# nrf9220_celldsp register map
Vendor: Nordic Semiconductor; Series: nRF92; File version: 1
Registers are 32-bit, read-write, reset 0x0 unless marked. A register's access mark holds for its fields unless they carry their own. Offsets are from the block's base; [hi:lo] are bit positions; lines under a group give offsets from that group; {n}, {i} and the like mark numbered series; 'fields as' and 'values as' point back to an identical list.

## GLOBAL_AHBBUFFER_APP — AHB Buffer 0
Base 0x5F90A000
Same registers: GLOBAL_AHBBUFFER_CELL 0x5F90C000
0x100 EVENTS_BUSERROR — Error response to posted write
  [0] EVENTS_BUSERROR
    0=NotGenerated (Event not generated); 1=Generated (Event generated)
0x200 SHORTS — Shortcuts between local events and tasks
0x300 INTEN — Enable or disable interrupt
  [0] BUSERROR — Enable or disable interrupt for event BUSERROR
    0=Disabled; 1=Enabled
0x304 INTENSET — Enable interrupt
  [0] BUSERROR — Write '1' to enable interrupt for event BUSERROR
    on read: 0=Disabled (Read: Disabled); 1=Enabled (Read: Enabled) | on write: 1=Set (Enable)
0x308 INTENCLR — Disable interrupt
  [0] BUSERROR — Write '1' to disable interrupt for event BUSERROR
    on read: 0=Disabled (Read: Disabled); 1=Enabled (Read: Enabled) | on write: 1=Clear (Disable)
0x30C INTPEND ro — Pending interrupts
  [0] BUSERROR — Read pending status of interrupt for event BUSERROR
    on read: 0=NotPending (Read: Not pending); 1=Pending (Read: Pending)
0x500 OPMODE — Operation mode
  [1:0] OPMODE
    0=f0 (Bypass); 1=f1 (Post all writes); 2=f2 (Obey hposted input); 3=f3 (Take OpMode from port)
0x504 ERRORADDRENABLE — Enable bit for error address tracking
  [0] ERRORADDRENABLE — Tracking must be enabled when it is needed. Detected error response for posted write (EVENT BUSERROR) will halt tracking and change the value of this register to 0.
    0=e0 (Error address is not tracked); 1=e1 (Error address is tracked)
0x508 ERRORADDR — Address for posted write error response
  [31:0] ERRORADDR — First address that caused error response for posted write. Valid only when EVENT BUSERROR is 1.

## GLOBAL_EGU130 — Event generator unit
Base 0x5F92D000
{0x0+4i} TASKS_TRIGGER[{i}] (i=0..15) wo — Description collection: Trigger n for triggering the corresponding TRIGGERED[n] event
  [0] TASKS_TRIGGER — Trigger n for triggering the corresponding TRIGGERED[n] event
    1=Trigger task
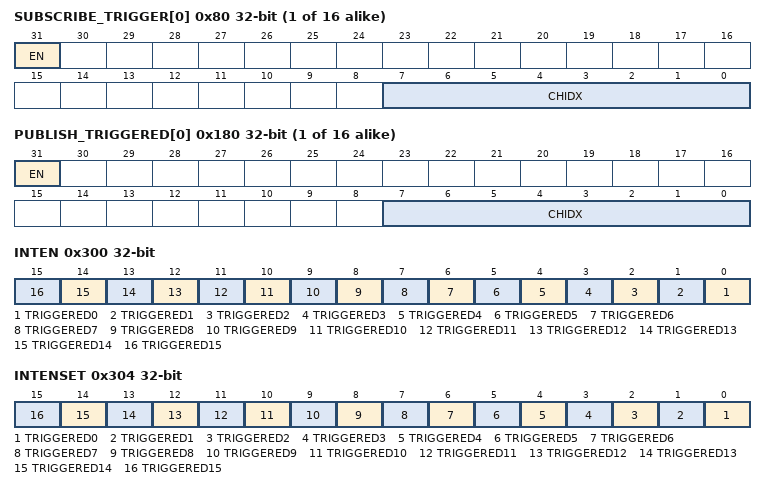
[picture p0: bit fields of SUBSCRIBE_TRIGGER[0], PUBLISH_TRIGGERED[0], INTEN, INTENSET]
{0x80+4i} SUBSCRIBE_TRIGGER[{i}] (i=0..15) — Description collection: Subscribe configuration for task TRIGGER[n]
  [31] EN
    0=Disabled (Disable subscription); 1=Enabled (Enable subscription)
  [7:0] CHIDX — DPPI channel that task TRIGGER[n] will subscribe to
{0x100+4i} EVENTS_TRIGGERED[{i}] (i=0..15) — Description collection: Event number n generated by triggering the corresponding TRIGGER[n] task
  [0] EVENTS_TRIGGERED — Event number n generated by triggering the corresponding TRIGGER[n] task
    0=NotGenerated (Event not generated); 1=Generated (Event generated)
{0x180+4i} PUBLISH_TRIGGERED[{i}] (i=0..15) — Description collection: Publish configuration for event TRIGGERED[n]
  [31] EN
    0=Disabled (Disable publishing); 1=Enabled (Enable publishing)
  [7:0] CHIDX — DPPI channel that event TRIGGERED[n] will publish to
0x300 INTEN — Enable or disable interrupt
  [all] fields
    0=Disabled; 1=Enabled
  [n] TRIGGERED{n} (n=0..15) — Enable or disable interrupt for event TRIGGERED[{n}]
0x304 INTENSET — Enable interrupt
  [all] fields
    on read: 0=Disabled (Read: Disabled); 1=Enabled (Read: Enabled) | on write: 1=Set (Enable)
  [n] TRIGGERED{n} (n=0..15) — Write '1' to enable interrupt for event TRIGGERED[{n}]
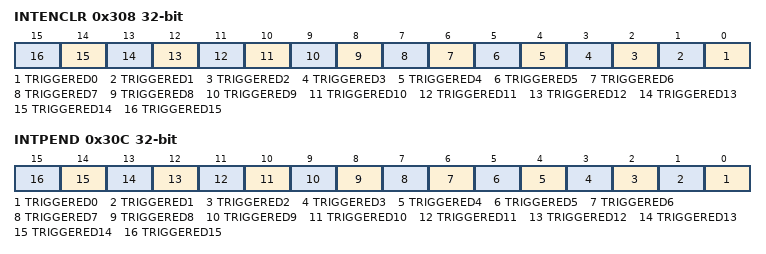
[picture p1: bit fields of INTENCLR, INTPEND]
0x308 INTENCLR — Disable interrupt
  [all] fields
    on read: 0=Disabled (Read: Disabled); 1=Enabled (Read: Enabled) | on write: 1=Clear (Disable)
  [n] TRIGGERED{n} (n=0..15) — Write '1' to disable interrupt for event TRIGGERED[{n}]
0x30C INTPEND ro — Pending interrupts
  [all] fields
    on read: 0=NotPending (Read: Not pending); 1=Pending (Read: Pending)
  [n] TRIGGERED{n} (n=0..15) — Read pending status of interrupt for event TRIGGERED[{n}]

## GLOBAL_GPIOINTERNAL — GPIO Internal
Base 0x5F939E00
0x40 LATCHCLRWAITCNT reset 0x2 — Select the number of wait cycles inserted on the bus when a LATCH register is cleared.
  [1:0] LATCHCLRWAITCNT
0x44 FORCELDETECTLOWCNT reset 0x8 — Select the number of cycles that LDETECT is forced low after clearing a LATCH register.
  [3:0] FORCELDETECTLOWCNT
0x48 RESET — Reset all GPIO registers.
  [0] RESET
    1=RESET (Trigger reset); 0=NA (No effect)
0x4C SENSECONFIGCHANGECNT reset 0x3 — Selects the number of cycles before the SENSE configuration takes effect when it is changed. Setting this register lower than the reset value can lead to unwanted LATCH set when SENSE and INPUT fields (PIN[n].CNF) are changed simultaneously.
  [2:0] SENSECONFIGCHANGECNT — Selects the number of cycles before the SENSE configuration takes effect when it is changed.
0x160 PCGC group — Unspecified
  0x00 TURNOFFAUTOCLOCKSOURCEREQ ro — No functionality
  {0x20+4j} PENALTY[{j}] (j=0..4) ro — Description collection: Penalty level for power/clock pair n
    [7:0] PENALTY — Penalty level
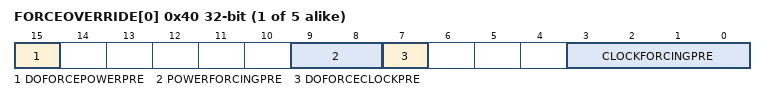
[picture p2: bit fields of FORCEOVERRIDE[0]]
  {0x40+4j} FORCEOVERRIDE[{j}] (j=0..4) ro — Description collection: Force override of power/clock pair n
    [15] DOFORCEPOWERPRE, [9:8] POWERFORCINGPRE, [7] DOFORCECLOCKPRE, [3:0] CLOCKFORCINGPRE

## GLOBAL_AUDIOPLLPM — AUXPM
Base 0x5F968000
0x20 TASKS_START wo — Request power up
  [0] TASKS_START
    1=Trigger task
0x24 TASKS_STOP wo — Stop requesting power up
  [0] TASKS_STOP
    1=Trigger task
0x110 EVENTS_SETTLED — LDO settled
  [0] EVENTS_SETTLED
    0=NotGenerated (Event not generated); 1=Generated (Event generated)
0x300 INTEN — Enable or disable interrupt
  [4] SETTLED — Enable or disable interrupt for event SETTLED
    0=Disabled; 1=Enabled
0x304 INTENSET — Enable interrupt
  [4] SETTLED — Write '1' to enable interrupt for event SETTLED
    on read: 0=Disabled (Read: Disabled); 1=Enabled (Read: Enabled) | on write: 1=Set (Enable)
0x308 INTENCLR — Disable interrupt
  [4] SETTLED — Write '1' to disable interrupt for event SETTLED
    on read: 0=Disabled (Read: Disabled); 1=Enabled (Read: Enabled) | on write: 1=Clear (Disable)
0x30C INTPEND ro — Pending interrupts
  [4] SETTLED — Read pending status of interrupt for event SETTLED
    on read: 0=NotPending (Read: Not pending); 1=Pending (Read: Pending)
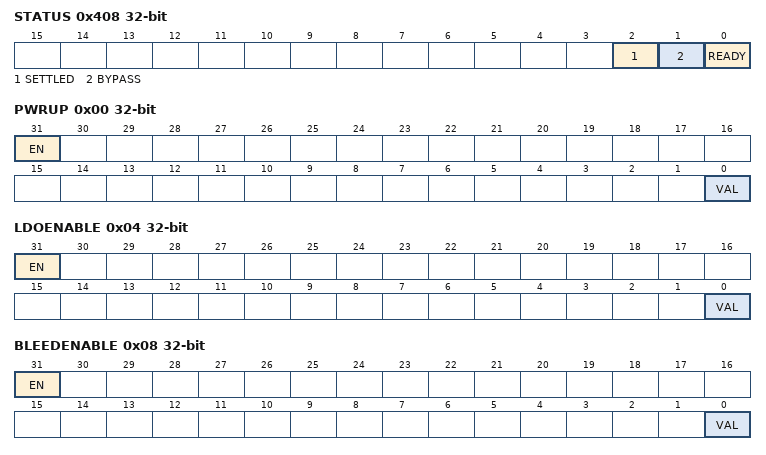
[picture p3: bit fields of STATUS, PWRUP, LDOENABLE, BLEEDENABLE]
0x408 STATUS ro — Status of AuxPm
  [2] SETTLED — LDO settled
    0=NotSettled (AuxPm not settled); 1=Settled (AuxPm settled)
  [1] BYPASS — Bypassing vref filter for startup boost
    0=NotBypass (VrefFilt not bypassed); 1=Bypass (VrefFilt bypassed)
  [0] READY — AuxPm powered up
    0=PowerDown (AuxPm powered down); 1=Powered (AuxPm powered up)
0x420 CONFIG group — Unspecified
  0x00 STARTUPTIME reset 0x18 — Time from pwrup to ready signal (0us-3us)
    [5:0] VAL — Timer value
      0=Min (0 us); 24=Default (1.5 us); 48=Max (3 us)
  0x04 SHUTDOWNTIME reset 0x18 — Time from shutdown until to ready signal is deasserted (0us-3us)
    fields as CONFIG.STARTUPTIME
  0x08 BYPASSTIME reset 0x70 — Time from ready until bypass vref turned off (7us-40us)
    [9:0] VAL — Timer value
      112=Min (7 us); 112=Default (7 us); 0x280=Max (40 us)
  0x0C SETLTIME reset 0x18 — Time from bypass turned off to settled (0us-3us)
    fields as CONFIG.STARTUPTIME
0x450 TRIM group — Unspecified
  0x00 VREFPM — Reference voltage trimming. Equals output voltage
    [2:0] VAL — Voltage trimming value.
      0=Val800mV (800 mV); 1=Val825mV (825 mV); 2=Val850mV (850 mV); 3=Val900mV (900 mV); 4=Val600mV (600 mV); 5=Val650mV (650 mV); 6=Val700mV (700 mV); 7=Val750mV (750 mV)
0x4F0 MIRROR — Enable LOCK for mirrored registers
  [0] LOCK — Lock for mirrored registers
    0=Disabled (Lock disabled); 1=Enabled (Lock enabled)
0x580 OVERRIDE group — Unspecified
  0x00 PWRUP — Override the pwrup to the analog module
    [31] EN — Enable the override
      0=Disabled (Override is disabled); 1=Enabled (Override is enabled)
    [0] VAL — Override value for the signal
  0x04 LDOENABLE — Override the LDO enable to the analog module
    fields as OVERRIDE.PWRUP
  0x08 BLEEDENABLE — Override the bleed enable to the analog module
    fields as OVERRIDE.PWRUP
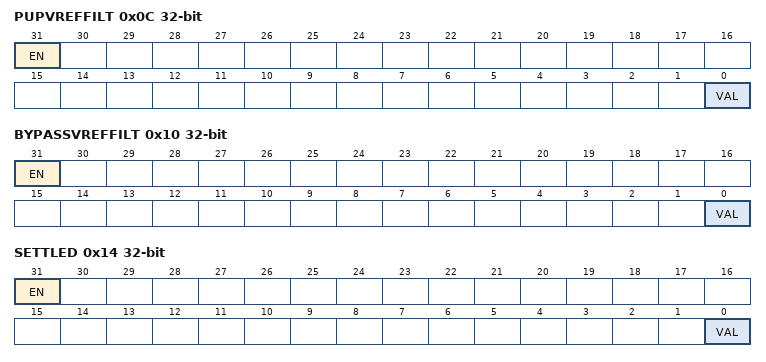
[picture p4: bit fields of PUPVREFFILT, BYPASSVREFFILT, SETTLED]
  0x0C PUPVREFFILT — Override the vref filter enable to the analog module
    fields as OVERRIDE.PWRUP
  0x10 BYPASSVREFFILT — Override the vref bypass to the analog module
    fields as OVERRIDE.PWRUP
  0x14 SETTLED — Override the SETTLED from the digital part
    fields as OVERRIDE.PWRUP
0x680 DFT group — Unspecified
  0x00 ATB0CONFIG — Analog Test Bus 0 (ATB0) configuration
    [31] EN
      0=Disabled (Analog test bus is disabled); 1=Enabled (Analog test bus is enabled)
  0x04 ATB1CONFIG — Analog Test Bus 1 (ATB1) configuration
    fields as DFT.ATB0CONFIG

## Notices in the file
Copyright (c) 2010 - 2025, Nordic Semiconductor ASA
All rights reserved.
Redistribution and use in source and binary forms, with or without modification,
are permitted provided that the following conditions are met:
1. Redistributions of source code must retain the above copyright notice, this
list of conditions and the following disclaimer.
2. Redistributions in binary form, except as embedded into a Nordic
Semiconductor ASA integrated circuit in a product or a software update for
such product, must reproduce the above copyright notice, this list of
conditions and the following disclaimer in the documentation and/or other
materials provided with the distribution.
3. Neither the name of Nordic Semiconductor ASA nor the names of its
contributors may be used to endorse or promote products derived from this
software without specific prior written permission.
4. This software, with or without modification, must only be used with a
Nordic Semiconductor ASA integrated circuit.
5. Any software provided in binary form under this license must not be reverse
engineered, decompiled, modified and/or disassembled.
THIS SOFTWARE IS PROVIDED BY NORDIC SEMICONDUCTOR ASA "AS IS" AND ANY EXPRESS
OR IMPLIED WARRANTIES, INCLUDING, BUT NOT LIMITED TO, THE IMPLIED WARRANTIES
OF MERCHANTABILITY, NONINFRINGEMENT, AND FITNESS FOR A PARTICULAR PURPOSE ARE
DISCLAIMED. IN NO EVENT SHALL NORDIC SEMICONDUCTOR ASA OR CONTRIBUTORS BE
LIABLE FOR ANY DIRECT, INDIRECT, INCIDENTAL, SPECIAL, EXEMPLARY, OR
CONSEQUENTIAL DAMAGES (INCLUDING, BUT NOT LIMITED TO, PROCUREMENT OF SUBSTITUTE
GOODS OR SERVICES; LOSS OF USE, DATA, OR PROFITS; OR BUSINESS INTERRUPTION)
HOWEVER CAUSED AND ON ANY THEORY OF LIABILITY, WHETHER IN CONTRACT, STRICT
LIABILITY, OR TORT (INCLUDING NEGLIGENCE OR OTHERWISE) ARISING IN ANY WAY OUT
OF THE USE OF THIS SOFTWARE, EVEN IF ADVISED OF THE POSSIBILITY OF SUCH DAMAGE.
